# MSP430FR2433 register map
Registers are 16-bit, read-write, reset 0x0 unless marked. A register's access mark holds for its fields unless they carry their own. Offsets are from the block's base; [hi:lo] are bit positions; {n}, {i} and the like mark numbered series.

## USCI_A0_SPI_MODE
Base 0x00000500
0x00 UCA0CTL1 8-bit — USCI A0 Control Register 1
0x01 UCA0CTL0 8-bit — USCI A0 Control Register 0
0x06 UCA0BR0 8-bit — USCI A0 Baud Rate 0
0x07 UCA0BR1 8-bit — USCI A0 Baud Rate 1
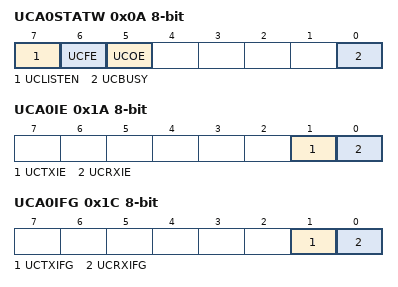
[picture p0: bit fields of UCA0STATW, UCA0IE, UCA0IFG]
0x0A UCA0STATW 8-bit — USCI A0 Status Register
  [7] UCLISTEN — USCI Listen mode
  [6] UCFE — USCI Frame Error Flag
  [5] UCOE — USCI Overrun Error Flag
  [0] UCBUSY — USCI Busy Flag
0x0C UCA0RXBUF — USCI A0 Receive Buffer
0x0E UCA0TXBUF — USCI A0 Transmit Buffer
0x1A UCA0IE 8-bit — USCI A0 Interrupt Enable Register
  [1] UCTXIE — USCI Transmit Interrupt Enable
  [0] UCRXIE — USCI Receive Interrupt Enable
0x1C UCA0IFG 8-bit — USCI A0 Interrupt Flags Register
  [1] UCTXIFG — SPI Transmit Interrupt Flag
  [0] UCRXIFG — SPI Receive Interrupt Flag
0x1E UCA0IV — USCI A0 Interrupt Vector Register

## USCI_A1_UART_MODE
Base 0x00000520
0x00 UCA1CTL1 8-bit — USCI A1 Control Register 1
0x01 UCA1CTL0 8-bit — USCI A1 Control Register 0
0x02 UCA1CTLW1 — USCI A1 Control Word Register 1
  [1:0] UCGLIT — USCI Deglitch Time Bit 1
    {v}=USCI Deglitch time: {v} (v=0..3)
0x06 UCA1BR0 8-bit — USCI A1 Baud Rate 0
0x07 UCA1BR1 8-bit — USCI A1 Baud Rate 1
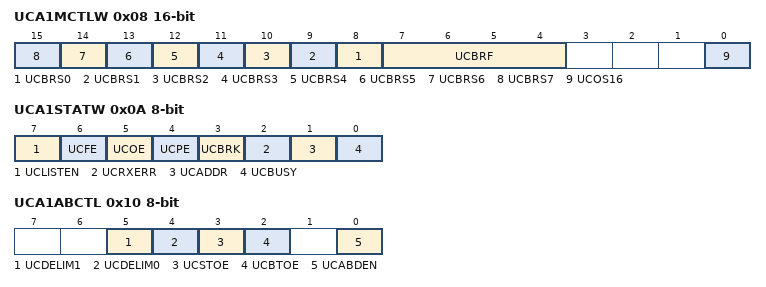
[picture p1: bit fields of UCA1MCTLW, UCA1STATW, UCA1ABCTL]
0x08 UCA1MCTLW — USCI A1 Modulation Control
  [n+8] UCBRS{n} (n=0..7) — USCI Second Stage Modulation Select {n}
  [7:4] UCBRF — USCI First Stage Modulation Select 3
    {v}=USCI First Stage Modulation: {v} (v=0..9); 10=USCI First Stage Modulation: A; 11=USCI First Stage Modulation: B; 12=USCI First Stage Modulation: C; 13=USCI First Stage Modulation: D; 14=USCI First Stage Modulation: E; 15=USCI First Stage Modulation: F
  [0] UCOS16 — USCI 16-times Oversampling enable
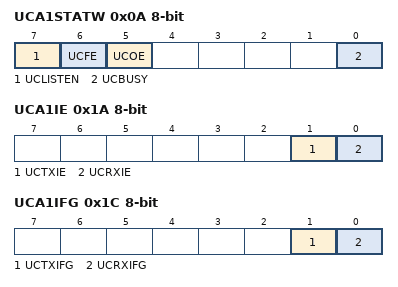
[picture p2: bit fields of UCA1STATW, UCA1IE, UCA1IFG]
0x0A UCA1STATW 8-bit — USCI A1 Status Register
  [7] UCLISTEN — USCI Listen mode
  [6] UCFE — USCI Frame Error Flag
  [5] UCOE — USCI Overrun Error Flag
  [4] UCPE — USCI Parity Error Flag
  [3] UCBRK — USCI Break received
  [2] UCRXERR — USCI RX Error Flag
  [1] UCADDR — USCI Address received Flag
  [0] UCBUSY — USCI Busy Flag
0x0C UCA1RXBUF — USCI A1 Receive Buffer
0x0E UCA1TXBUF — USCI A1 Transmit Buffer
0x10 UCA1ABCTL 8-bit — USCI A1 LIN Control
  [5] UCDELIM1 — Break Sync Delimiter 1
  [4] UCDELIM0 — Break Sync Delimiter 0
  [3] UCSTOE — Sync-Field Timeout error
  [2] UCBTOE — Break Timeout error
  [0] UCABDEN — Auto Baud Rate detect enable
0x12 UCA1IRTCTL 8-bit — USCI A1 IrDA Transmit Control
0x13 UCA1IRRCTL 8-bit — USCI A1 IrDA Receive Control
0x1E UCA1IV — USCI A1 Interrupt Vector Register

## USCI_A1_SPI_MODE
Base 0x00000520
0x00 UCA1CTL1 8-bit — USCI A1 Control Register 1
0x01 UCA1CTL0 8-bit — USCI A1 Control Register 0
0x06 UCA1BR0 8-bit — USCI A1 Baud Rate 0
0x07 UCA1BR1 8-bit — USCI A1 Baud Rate 1
0x0A UCA1STATW 8-bit — USCI A1 Status Register
  [7] UCLISTEN — USCI Listen mode
  [6] UCFE — USCI Frame Error Flag
  [5] UCOE — USCI Overrun Error Flag
  [0] UCBUSY — USCI Busy Flag
0x0C UCA1RXBUF — USCI A1 Receive Buffer
0x0E UCA1TXBUF — USCI A1 Transmit Buffer
0x1A UCA1IE 8-bit — USCI A1 Interrupt Enable Register
  [1] UCTXIE — USCI Transmit Interrupt Enable
  [0] UCRXIE — USCI Receive Interrupt Enable
0x1C UCA1IFG 8-bit — USCI A1 Interrupt Flags Register
  [1] UCTXIFG — SPI Transmit Interrupt Flag
  [0] UCRXIFG — SPI Receive Interrupt Flag
0x1E UCA1IV — USCI A1 Interrupt Vector Register

## SFR — SFR Special Function Registers
Base 0x00000100
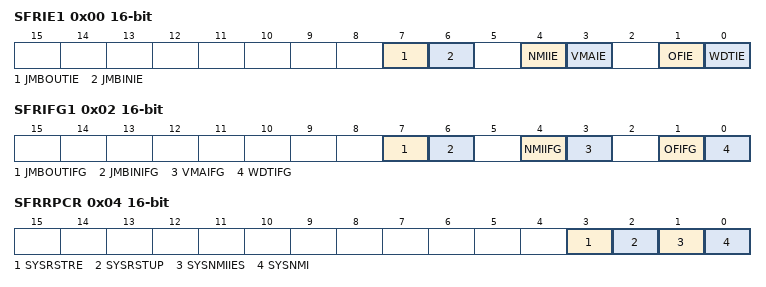
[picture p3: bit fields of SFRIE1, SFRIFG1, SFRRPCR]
0x00 SFRIE1 — Interrupt Enable 1
  [7] JMBOUTIE — JTAG Mail Box output Interrupt Enable
  [6] JMBINIE — JTAG Mail Box input Interrupt Enable
  [4] NMIIE — NMI Interrupt Enable
  [3] VMAIE — Vacant Memory Interrupt Enable
  [1] OFIE — Osc Fault Enable
  [0] WDTIE — WDT Interrupt Enable
0x02 SFRIFG1 — Interrupt Flag 1
  [7] JMBOUTIFG — JTAG Mail Box output Interrupt Flag
  [6] JMBINIFG — JTAG Mail Box input Interrupt Flag
  [4] NMIIFG — NMI Interrupt Flag
  [3] VMAIFG — Vacant Memory Interrupt Flag
  [1] OFIFG — Osc Fault Flag
  [0] WDTIFG — WDT Interrupt Flag
0x04 SFRRPCR — RESET Pin Control Register
  [3] SYSRSTRE — RESET Pin Resistor enable
  [2] SYSRSTUP — RESET Pin pull down/up select
  [1] SYSNMIIES — NMI edge select
  [0] SYSNMI — NMI select
